AUTOSAR XML (schema 4-0-3)
standard types defined: Boolean, UInt32, UInt8
package /AUTOSAR_Platform/DataConstrs
  range DC_Boolean: raw 0..1
  range DC_UInt8: raw 0..255
package /PATAC/MSM/ComponentTypes
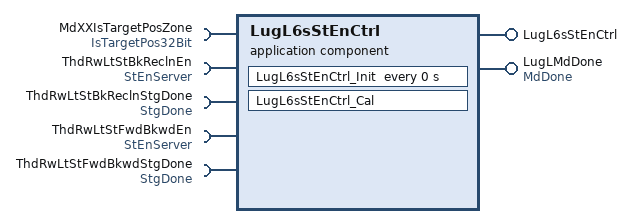
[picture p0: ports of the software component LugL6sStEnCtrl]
  application sw component type LugL6sStEnCtrl
    provide port LugL6sStEnCtrl: server-com-spec{operation=Cal, queue-length=1}, provided-interface=LugL6sStEnCtrl
    provide port LugLMdDone: nonqueued-sender-com-spec{data-element=MdDone/Val, init-value=0}, provided-interface=MdDone
    5 x require port:
      MdXXIsTargetPosZone: nonqueued-receiver-com-spec{data-element=IsTargetPos32Bit/Val, filter=data-filter-type=ALWAYS, init-value=0}, required-interface=IsTargetPos32Bit
      ThdRwLtStBkReclnEn: required-com-specs=[Clear, Get, Set], required-interface=StEnServer
      ThdRwLtStBkReclnStgDone: nonqueued-receiver-com-spec{data-element=StgDone/Val, filter=data-filter-type=ALWAYS, init-value=0}, required-interface=StgDone
      ThdRwLtStFwdBkwdEn: required-com-specs=[Clear, Get, Set], required-interface=StEnServer
      ThdRwLtStFwdBkwdStgDone: nonqueued-receiver-com-spec{data-element=StgDone/Val, filter=data-filter-type=ALWAYS, init-value=0}, required-interface=StgDone
    behavior LugL6sStEnCtrl_InternalBehavior
      operation invoked event OIT_LugL6sStEnCtrl_Cal_LugL6sStEnCtrl_Cal: start-on-event=LugL6sStEnCtrl_Cal, operation=LugL6sStEnCtrl.Cal
      timing event LugL6sStEnCtrl_InitEvent: start-on-event=LugL6sStEnCtrl_Init, period=0
      runnable LugL6sStEnCtrl_Cal
        data-receive-point-by-arguments:
          access REC_MdXXIsTargetPosZone_Val: accessed-variable=MdXXIsTargetPosZone.Val
          access REC_ThdRwLtStBkReclnStgDone_Val: accessed-variable=ThdRwLtStBkReclnStgDone.Val
          access REC_ThdRwLtStFwdBkwdStgDone_Val: accessed-variable=ThdRwLtStFwdBkwdStgDone.Val
        data-send-points:
          access SEND_LugLMdDone_Val: accessed-variable=LugLMdDone.Val
        4 x sync call, all with timeout=0:
          SC_ThdRwLtStBkReclnEn_Clear: operation=ThdRwLtStBkReclnEn.Clear
          SC_ThdRwLtStBkReclnEn_Set: operation=ThdRwLtStBkReclnEn.Set
          SC_ThdRwLtStFwdBkwdEn_Clear: operation=ThdRwLtStFwdBkwdEn.Clear
          SC_ThdRwLtStFwdBkwdEn_Set: operation=ThdRwLtStFwdBkwdEn.Set
      runnable LugL6sStEnCtrl_Init
  swc implementation LugL6sStEnCtrl_Implementation: behavior=LugL6sStEnCtrl_InternalBehavior
    code-descriptors:
      code Default: artifact-descriptors=autosar-engineering-object={short-label=Default, category=SWSRC}
package /PATAC/MSM/ModeAdjust/PortInterface
  client server interface LugL6sStEnCtrl
    operation Cal
  client server interface StEnServer
    operation Clear
      arg data: type=UInt8, direction=IN, server-argument-impl-policy=USE-ARGUMENT-TYPE
    operation Get
      arg data: type=UInt32, direction=OUT, server-argument-impl-policy=USE-ARGUMENT-TYPE
    operation Set
      arg data: type=UInt8, direction=IN, server-argument-impl-policy=USE-ARGUMENT-TYPE
  sender receiver interface IsTargetPos32Bit: invalidation-policy{data-element=IsTargetPos32Bit/Val, handle-invalid=DONT-INVALIDATE}
    data Val: type=UInt32
  sender receiver interface MdDone: invalidation-policy{data-element=MdDone/Val, handle-invalid=DONT-INVALIDATE}
    data Val: type=UInt8
  sender receiver interface StgDone: invalidation-policy{data-element=StgDone/Val, handle-invalid=DONT-INVALIDATE}
    data Val: type=Boolean
